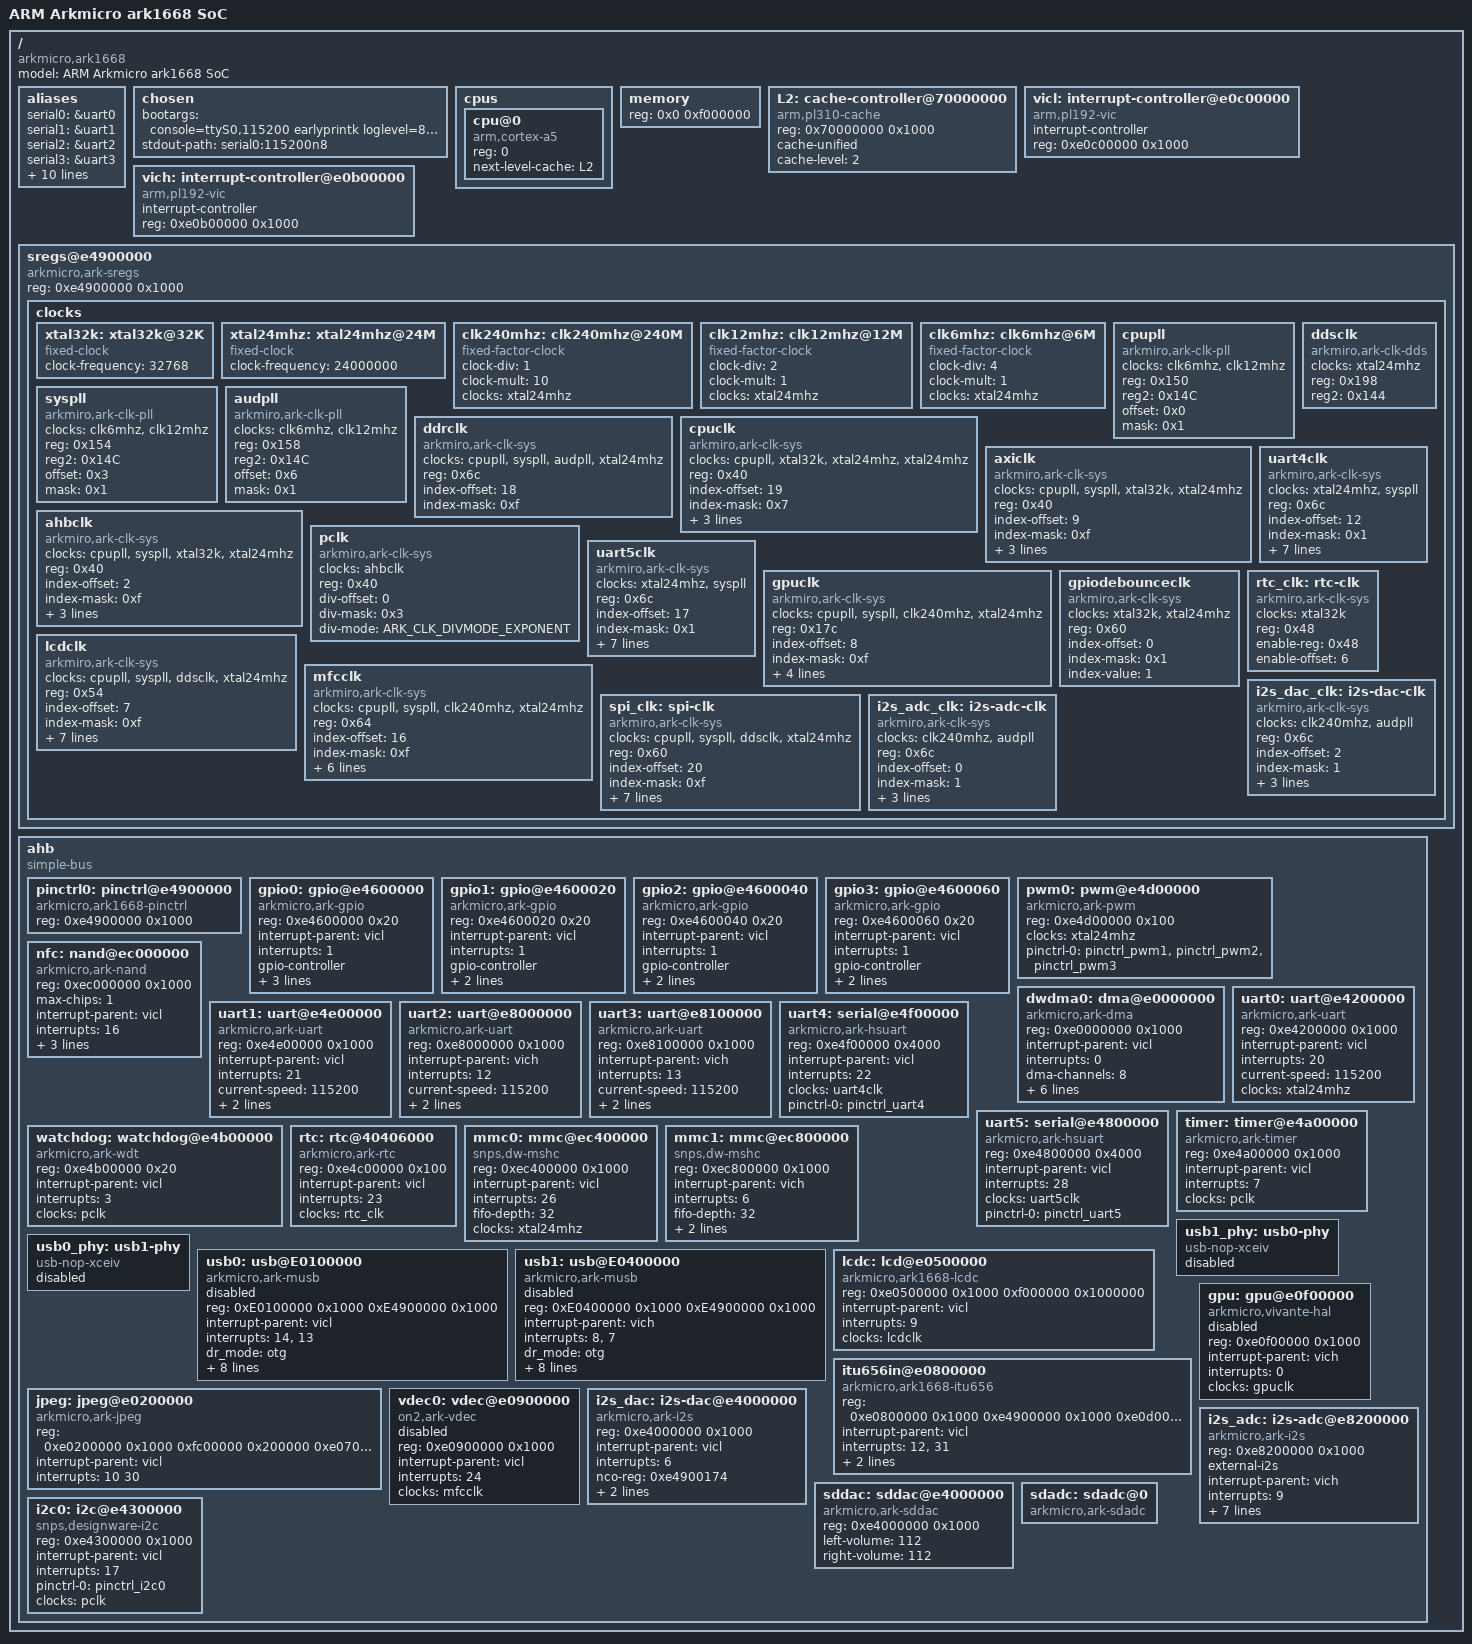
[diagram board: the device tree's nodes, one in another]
/include/ "skeleton.dtsi"
#include <dt-bindings/interrupt-controller/irq.h>
#include <dt-bindings/clock/ark-clk.h>

/ {
	model = "ARM Arkmicro ark1668 SoC";
	compatible = "arkmicro,ark1668";

	aliases {
		serial0 = &uart0;
		serial1 = &uart1;
		serial2 = &uart2;
		serial3 = &uart3;
		hsserial0 = &uart4;
		hsserial1 = &uart5;
		gpio0 = &gpio0;
		gpio1 = &gpio1;
		gpio2 = &gpio2;
		gpio3 = &gpio3;
        usb0 = &usb0;
        usb1 = &usb1;
        phy0 = &usb0_phy;
        phy1 = &usb1_phy;
	};

	chosen {
		bootargs = "console=ttyS0,115200 earlyprintk loglevel=8 clk_ignore_unused";
		stdout-path = "serial0:115200n8";
	};

	cpus {
		#address-cells = <1>;
		#size-cells = <0>;

		cpu@0 {
			device_type = "cpu";
			compatible = "arm,cortex-a5";
			reg = <0>;
			next-level-cache = <&L2>;
		};
	};

	memory {
		reg = <0x0 0xf000000>;	//2Gb
		//reg = <0x0 0x8000000>;	//1Gb
	};

	L2: cache-controller@70000000 {
		compatible = "arm,pl310-cache";
		reg = <0x70000000 0x1000>;
		cache-unified;
		cache-level = <2>;
	};

	vicl: interrupt-controller@e0c00000 {
		compatible = "arm,pl192-vic";
		interrupt-controller;
		reg = <0xe0c00000 0x1000>;
		#interrupt-cells = <1>;
	};

	vich: interrupt-controller@e0b00000 {
		compatible = "arm,pl192-vic";
		interrupt-controller;
		reg = <0xe0b00000 0x1000>;
		#interrupt-cells = <1>;
	};

	sregs@e4900000 {
		compatible = "arkmicro,ark-sregs";
		reg = <0xe4900000 0x1000>;

		clocks {
			#address-cells = <1>;
			#size-cells = <0>;

			xtal32k: xtal32k@32K {
				#clock-cells = <0>;
				compatible = "fixed-clock";
				clock-frequency = <32768>;
			};

			xtal24mhz: xtal24mhz@24M {
				#clock-cells = <0>;
				compatible = "fixed-clock";
				clock-frequency = <24000000>;
			};

			clk240mhz: clk240mhz@240M {
				#clock-cells = <0>;
				compatible = "fixed-factor-clock";
				clock-div = <1>;
				clock-mult = <10>;
				clocks = <&xtal24mhz>;
			};

			clk12mhz: clk12mhz@12M {
				#clock-cells = <0>;
				compatible = "fixed-factor-clock";
				clock-div = <2>;
				clock-mult = <1>;
				clocks = <&xtal24mhz>;
			};

			clk6mhz: clk6mhz@6M {
				#clock-cells = <0>;
				compatible = "fixed-factor-clock";
				clock-div = <4>;
				clock-mult = <1>;
				clocks = <&xtal24mhz>;
			};

			cpupll: cpupll {
				#clock-cells = <0>;
				compatible = "arkmiro,ark-clk-pll";
				clocks = <&clk6mhz>, <&clk12mhz>;
				reg = <0x150>;
				reg2 = <0x14C>;
				offset = <0x0>;
				mask = <0x1>;
			};

			syspll: syspll {
				#clock-cells = <0>;
				compatible = "arkmiro,ark-clk-pll";
				clocks = <&clk6mhz>, <&clk12mhz>;
				reg = <0x154>;
				reg2 = <0x14C>;
				offset = <0x3>;
				mask = <0x1>;
			};

			audpll: audpll {
				#clock-cells = <0>;
				compatible = "arkmiro,ark-clk-pll";
				clocks = <&clk6mhz>, <&clk12mhz>;
				reg = <0x158>;
				reg2 = <0x14C>;
				offset = <0x6>;
				mask = <0x1>;
			};

			ddsclk: ddsclk {
				#clock-cells = <0>;
				compatible = "arkmiro,ark-clk-dds";
				clocks = <&xtal24mhz>;
				reg = <0x198>;
				reg2 = <0x144>;
			};

			ddrclk: ddrclk {
				#clock-cells = <0>;
				compatible = "arkmiro,ark-clk-sys";
				clocks = <&cpupll>, <&syspll>, <&audpll>, <&xtal24mhz>;
				reg = <0x6c>;
				index-offset = <18>;
				index-mask = <0xf>;
			};

			cpuclk: cpuclk {
				#clock-cells = <0>;
				compatible = "arkmiro,ark-clk-sys";
				clocks = <&cpupll>, <&xtal32k>, <&xtal24mhz>, <&xtal24mhz>;
				reg = <0x40>;
				index-offset = <19>;
				index-mask = <0x7>;
				div-offset = <22>;
				div-mask = <0x7>;
				div-mode = <ARK_CLK_DIVMODE_NOZERO>;
			};

			axiclk: axiclk {
				#clock-cells = <0>;
				compatible = "arkmiro,ark-clk-sys";
				clocks = <&cpupll>, <&syspll>, <&xtal32k>, <&xtal24mhz>;
				reg = <0x40>;
				index-offset = <9>;
				index-mask = <0xf>;
				div-offset = <13>;
				div-mask = <0x7>;
				div-mode = <ARK_CLK_DIVMODE_NOZERO>;
			};

			ahbclk: ahbclk {
				#clock-cells = <0>;
				compatible = "arkmiro,ark-clk-sys";
				clocks = <&cpupll>, <&syspll>, <&xtal32k>, <&xtal24mhz>;
				reg = <0x40>;
				index-offset = <2>;
				index-mask = <0xf>;
				div-offset = <6>;
				div-mask = <0x7>;
				div-mode = <ARK_CLK_DIVMODE_NOZERO>;
			};

			pclk: pclk {
				#clock-cells = <0>;
				compatible = "arkmiro,ark-clk-sys";
				clocks = <&ahbclk>;
				reg = <0x40>;
				div-offset = <0>;
				div-mask = <0x3>;
				div-mode = <ARK_CLK_DIVMODE_EXPONENT>;
			};

			uart4clk: uart4clk {
				#clock-cells = <0>;
				compatible = "arkmiro,ark-clk-sys";
				clocks = <&xtal24mhz>, <&syspll>;
				reg = <0x6c>;
				index-offset = <12>;
				index-mask = <0x1>;
				index-value = <0>;
				div-offset = <8>;
				div-mask = <0xf>;
				div-value = <0>;
				div-mode = <ARK_CLK_DIVMODE_NOZERO>;
				enable-reg = <0x48 0x50>;
				enable-offset = <9 9>;
			};

			uart5clk: uart5clk {
				#clock-cells = <0>;
				compatible = "arkmiro,ark-clk-sys";
				clocks = <&xtal24mhz>, <&syspll>;
				reg = <0x6c>;
				index-offset = <17>;
				index-mask = <0x1>;
				index-value = <0>;
				div-offset = <13>;
				div-mask = <0xf>;
				div-value = <0>;
				div-mode = <ARK_CLK_DIVMODE_NOZERO>;
				enable-reg = <0x48 0x50>;
				enable-offset = <10 10>;
			};

			gpuclk: gpuclk {
				#clock-cells = <0>;
				compatible = "arkmiro,ark-clk-sys";
				clocks = <&cpupll>, <&syspll>, <&clk240mhz>, <&xtal24mhz>;
				reg = <0x17c>;
				index-offset = <8>;
				index-mask = <0xf>;
				index-value = <1>;
				div-offset = <12>;
				div-mask = <0x7>;
				div-mode = <ARK_CLK_DIVMODE_NOZERO>;
			};

			gpiodebounceclk: gpiodebounceclk {
				#clock-cells = <0>;
				compatible = "arkmiro,ark-clk-sys";
				clocks = <&xtal32k>, <&xtal24mhz>;
				reg = <0x60>;
				index-offset = <0>;
				index-mask = <0x1>;
				index-value = <1>;
			};

			lcdclk: lcdclk {
				#clock-cells = <0>;
				compatible = "arkmiro,ark-clk-sys";
				clocks = <&cpupll>, <&syspll>, <&ddsclk>, <&xtal24mhz>;
				reg = <0x54>;
				index-offset = <7>;
				index-mask = <0xf>;
				index-value = <1>;
				div-offset = <19>;
				div-mask = <0xf>;
				div-value = <1>;
				clk-can-change;
				enable-reg = <0x44 0x4c 0x50>;
				enable-offset = <8 1 4>;
			};

			mfcclk: mfcclk {
				#clock-cells = <0>;
				compatible = "arkmiro,ark-clk-sys";
				clocks = <&cpupll>, <&syspll>, <&clk240mhz>, <&xtal24mhz>;
				reg = <0x64>;
				index-offset = <16>;
				index-mask = <0xf>;
				index-value = <1>;
				div-offset = <20>;
				div-mask = <0x7>;
				div-value = <2>;
				enable-reg = <0x44 0x4c 0x50>;
				enable-offset = <9 3 22>;
			};

			rtc_clk: rtc-clk {
				#clock-cells = <0>;
				compatible = "arkmiro,ark-clk-sys";
				clocks = <&xtal32k>;
				reg = <0x48>;
				enable-reg = <0x48>;
				enable-offset = <6>;
			};

			spi_clk: spi-clk {
				#clock-cells = <0>;
				compatible = "arkmiro,ark-clk-sys";
				clocks = <&cpupll>, <&syspll>, <&ddsclk>, <&xtal24mhz>;
				reg = <0x60>;
				index-offset = <20>;
				index-mask = <0xf>;
				index-value = <1>;
				div-offset = <16>;
				div-mask = <0xf>;
				div-value = <2>;
				div-mode = <ARK_CLK_DIVMODE_PONEDOUBLE>;
				enable-reg = <0x48 0x50>;
				enable-offset = <4 13>;
			};

			i2s_dac_clk: i2s-dac-clk {
				#clock-cells = <0>;
				compatible = "arkmiro,ark-clk-sys";
				clocks = <&clk240mhz>, <&audpll>;
				reg = <0x6c>;
				index-offset = <2>;
				index-mask = <1>;
				index-value = <0>;
				enable-reg = <0x48 0x50 0x50>;
				enable-offset = <1 14 15>;
			};

			i2s_adc_clk: i2s-adc-clk {
				#clock-cells = <0>;
				compatible = "arkmiro,ark-clk-sys";
				clocks = <&clk240mhz>, <&audpll>;
				reg = <0x6c>;
				index-offset = <0>;
				index-mask = <1>;
				index-value = <0>;
				enable-reg = <0x48 0x4c 0x4c>;
				enable-offset = <17 21 22>;
			};
		};
	};

	ahb {
		compatible = "simple-bus";
		#address-cells = <1>;
		#size-cells = <1>;
		ranges;

		pinctrl0: pinctrl@e4900000 {
			compatible = "arkmicro,ark1668-pinctrl";
			reg = <0xe4900000 0x1000>;
		};

		gpio0: gpio@e4600000 {
			compatible = "arkmicro,ark-gpio";
			reg = <0xe4600000 0x20>;
			interrupt-parent = <&vicl>;
			interrupts = <1>;
			#gpio-cells = <2>;
			gpio-controller;
			interrupt-controller;
			#interrupt-cells = <2>;
			clocks = <&gpiodebounceclk>;
			gpio-ranges = <&pinctrl0 6 6 2>, <&pinctrl0 10 10 22>;
		};

		gpio1: gpio@e4600020 {
			compatible = "arkmicro,ark-gpio";
			reg = <0xe4600020 0x20>;
			interrupt-parent = <&vicl>;
			interrupts = <1>;
			#gpio-cells = <2>;
			gpio-controller;
			interrupt-controller;
			#interrupt-cells = <2>;
			gpio-ranges = <&pinctrl0 0 32 32>;
		};

		gpio2: gpio@e4600040 {
			compatible = "arkmicro,ark-gpio";
			reg = <0xe4600040 0x20>;
			interrupt-parent = <&vicl>;
			interrupts = <1>;
			#gpio-cells = <2>;
			gpio-controller;
			interrupt-controller;
			#interrupt-cells = <2>;
			gpio-ranges = <&pinctrl0 0 64 32>;
		};

		gpio3: gpio@e4600060 {
			compatible = "arkmicro,ark-gpio";
			reg = <0xe4600060 0x20>;
			interrupt-parent = <&vicl>;
			interrupts = <1>;
			#gpio-cells = <2>;
			gpio-controller;
			interrupt-controller;
			#interrupt-cells = <2>;
			gpio-ranges = <&pinctrl0 0 96 32>;
		};

		pwm0: pwm@e4d00000 {
			compatible = "arkmicro,ark-pwm";
			reg = <0xe4d00000 0x100>;
			#pwm-cells = <2>;
			clocks = <&xtal24mhz>;
			pinctrl-names = "default";
			pinctrl-0 = <&pinctrl_pwm1 &pinctrl_pwm2 &pinctrl_pwm3>;
		};

		nfc: nand@ec000000 {
			compatible = "arkmicro,ark-nand";
			reg = <0xec000000 0x1000>;
			max-chips = <1>;
			interrupt-parent = <&vicl>;
			interrupts = <16>;
			nand-bus-width = <8>;
			nand-ecc-mode = "hw_syndrome";
			nand-on-flash-bbt;
		};

		dwdma0: dma@e0000000 {
			compatible = "arkmicro,ark-dma";
			reg = <0xe0000000 0x1000>;
			interrupt-parent = <&vicl>;
			interrupts = <0>;
			dma-channels = <8>;
			dma-masters = <2>;
			chan_allocation_order = <1>;
			chan_priority = <1>;
			block_size = <0xfff>;
			data-width = <4 4>;
			/* multi-block = <1 1 1 1 1 1 1 1>; */
			clocks = <&ahbclk>;
			clock-names = "hclk";
			#dma-cells = <3>;
		};

		uart0: uart@e4200000 {
			compatible = "arkmicro,ark-uart";
			reg = <0xe4200000 0x1000>;
			interrupt-parent = <&vicl>;
			interrupts = <20>;
			current-speed = <115200>;
			clocks = <&xtal24mhz>;
			//dmas = <&dwdma0 6 1 0>, <&dwdma0 7 0 1>;
			//dma-names = "rx", "tx";
			//pinctrl-names = "default";
			//pinctrl-0 = <&pinctrl_uart0>;
		};

		uart1: uart@e4e00000 {
			compatible = "arkmicro,ark-uart";
			reg = <0xe4e00000 0x1000>;
			interrupt-parent = <&vicl>;
			interrupts = <21>;
			current-speed = <115200>;
			clocks = <&xtal24mhz>;
			pinctrl-names = "default";
			pinctrl-0 = <&pinctrl_uart1>;
		};

		uart2: uart@e8000000 {
			compatible = "arkmicro,ark-uart";
			reg = <0xe8000000 0x1000>;
			interrupt-parent = <&vich>;
			interrupts = <12>;
			current-speed = <115200>;
			clocks = <&xtal24mhz>;
			pinctrl-names = "default";
			pinctrl-0 = <&pinctrl_uart2>;
		};

		uart3: uart@e8100000 {
			compatible = "arkmicro,ark-uart";
			reg = <0xe8100000 0x1000>;
			interrupt-parent = <&vich>;
			interrupts = <13>;
			current-speed = <115200>;
			clocks = <&xtal24mhz>;
			//dmas = <&dwdma0 21 1 0>, <&dwdma0 22 0 1>;
			//dma-names = "rx", "tx";
			pinctrl-names = "default";
			pinctrl-0 = <&pinctrl_uart3>;
		};

		uart4: serial@e4f00000 {
			compatible = "arkmicro,ark-hsuart";
			reg = <0xe4f00000 0x4000>;
			interrupt-parent = <&vicl>;
			interrupts = <22>;
			clocks = <&uart4clk>;
			pinctrl-names = "default";
			pinctrl-0 = <&pinctrl_uart4>;
		};

		uart5: serial@e4800000 {
			compatible = "arkmicro,ark-hsuart";
			reg = <0xe4800000 0x4000>;
			interrupt-parent = <&vicl>;
			interrupts = <28>;
			clocks = <&uart5clk>;
			pinctrl-names = "default";
			pinctrl-0 = <&pinctrl_uart5>;
		};

		timer: timer@e4a00000 {
			compatible = "arkmicro,ark-timer";
			reg = <0xe4a00000 0x1000>;
			interrupt-parent = <&vicl>;
			interrupts = <7>;
			clocks = <&pclk>;
		};

		watchdog: watchdog@e4b00000 {
			compatible = "arkmicro,ark-wdt";
			reg = <0xe4b00000 0x20>;
			interrupt-parent = <&vicl>;
			interrupts = <3>;
			clocks = <&pclk>;
		};

		rtc: rtc@40406000 {
			compatible = "arkmicro,ark-rtc";
			reg = <0xe4c00000 0x100>;
			interrupt-parent = <&vicl>;
			interrupts = <23>;
			clocks = <&rtc_clk>;
		};

		mmc0: mmc@ec400000 {
			compatible = "snps,dw-mshc";
			#address-cells = <1>;
			#size-cells = <0>;
			reg = <0xec400000 0x1000>;
			interrupt-parent = <&vicl>;
			interrupts = <26>;
			fifo-depth = <32>;
			//dmas = <&dwdma0 8 1 0>;
			//dma-names = "rx-tx";
			clocks = <&xtal24mhz>;
			clock-names = "ciu";
		};

		mmc1: mmc@ec800000 {
			compatible = "snps,dw-mshc";
			#address-cells = <1>;
			#size-cells = <0>;
			reg = <0xec800000 0x1000>;
			interrupt-parent = <&vich>;
			interrupts = <6>;
			fifo-depth = <32>;
			dmas = <&dwdma0 9 1 0>;
			dma-names = "rx-tx";
			clocks = <&xtal24mhz>;
			clock-names = "ciu";
		};

        usb1_phy: usb0-phy {
            compatible = "usb-nop-xceiv";
            #phy-cells = <0>;
            status = "disabled";
        };

        usb0_phy: usb1-phy {
            compatible = "usb-nop-xceiv";
            #phy-cells = <0>;
            status = "disabled";
        };

        usb0: usb@E0100000{
            compatible = "arkmicro,ark-musb";
            status = "disabled";
            reg = <0xE0100000 0x1000    /* usb0 base address */
                    0xE4900000 0x1000>; /* ahb sys base address */
            reg-names = "system", "control";
			interrupt-parent = <&vicl>;
            interrupts = <14>, <13>; /* <usb0 int>, <usb0_dma_int> */
            interrupt-names = "mc", "dma";
            dr_mode = "otg";
            multipoint = <1>;
            num-eps = <6>;
            ram-bits = <12>;
            //power = <500>;
            phys = <&usb0_phy>;
            gpio-id = <76>;
            gpio-pwr = <126>;
            sys-softrest-regoffset = <0x74>;
            usb-softrest-bitoffset = <5>;
            //dma = <1>;  /* 0:false; 1:true */
            //dma_channels = <2>; /* dma ch nums */
        };

        usb1: usb@E0400000{
            compatible = "arkmicro,ark-musb";
            status = "disabled";
            reg = <0xE0400000 0x1000    /*  usb1 base address */
                    0xE4900000 0x1000>; /* ahb sys base address */
            reg-names = "system", "control";
			interrupt-parent = <&vich>;
            interrupts = <8>, <7>; /* <usb1 int>, <usb1_dma_int> */
            interrupt-names = "mc", "dma";
            dr_mode = "otg";
            multipoint = <1>;
            num-eps = <6>;
            ram-bits = <12>;
            //power = <500>;
            phys = <&usb1_phy>;
            gpio-id = <1>;
            gpio-pwr = <117>;
            sys-softrest-regoffset = <0x78>;
            usb-softrest-bitoffset = <6>;
            //dma = <1>;  /* 0:false; 1:true */
            //dma_channels = <2>; /* dma ch nums */
        };

		lcdc: lcd@e0500000 {
			compatible = "arkmicro,ark1668-lcdc";
			reg = <0xe0500000 0x1000
					0xf000000 0x1000000>;
			interrupt-parent = <&vicl>;
			interrupts = <9>;
			clocks = <&lcdclk>;
			clock-names = "lcdc_clk";
		};

		itu656in@e0800000 {
			compatible = "arkmicro,ark1668-itu656";
			reg = <0xe0800000 0x1000
				   0xe4900000 0x1000
				   0xe0d00000 0x1000
				   0xe0500000 0x1000>;
			interrupt-parent = <&vicl>;
			interrupts = <12>, <31>;
			channel = <1>;
			mirror = <0>;
		};
		
		/*itu656in@e0800000 {
                        compatible = "arkmicro,ark1668-vin";
                        reg = <0xe0800000 0x1000
                                   0xe4900000 0x1000
                                   0xe0d00000 0x1000
                                   0xe0500000 0x1000>;
                        interrupt-parent = <&vicl>;
                        interrupts = <12>, <31>;
                        channel = <1>;
                        mirror = <0>;

                        port{
                        ark656: endpoint@1{
                                remote-endpoint = <&ark7116>;
                                };
                        };

                };*/


		gpu: gpu@e0f00000 {
			compatible = "arkmicro,vivante-hal";
			reg = <0xe0f00000 0x1000>;
			interrupt-parent = <&vich>;
			interrupts = <0>;
			clocks = <&gpuclk>;
			status = "disabled";
		};

		jpeg: jpeg@e0200000 {
			compatible = "arkmicro,ark-jpeg";
			reg = <0xe0200000 0x1000
				   0xfc00000 0x200000
				   0xe0700000 0x1000>;
			interrupt-parent = <&vicl>;
			interrupts = <10 30>;
		};

		vdec0: vdec@e0900000 {
			compatible = "on2,ark-vdec";
			status = "disabled";
			reg = <0xe0900000 0x1000>;
			interrupt-parent = <&vicl>;
			interrupts = <24>;
			clocks = <&mfcclk>;
			clock-names = "vdec_clk";
		};

		i2s_dac: i2s-dac@e4000000 {
			compatible = "arkmicro,ark-i2s";
			reg = <0xe4000000 0x1000>;
			interrupt-parent = <&vicl>;
			interrupts = <6>;
			nco-reg = <0xe4900174>;
			dmas = <&dwdma0 0 1 0>, <&dwdma0 1 0 1>;
			dma-names = "rx", "tx";
			clocks = <&i2s_dac_clk>;
			#sound-dai-cells = <0>;
		};

		i2s_adc: i2s-adc@e8200000 {
			compatible = "arkmicro,ark-i2s";
			reg = <0xe8200000 0x1000>;
			external-i2s;
			interrupt-parent = <&vich>;
			interrupts = <9>;
			nco-reg = <0xe4900178>;
			dmas = <&dwdma0 23 1 0>, <&dwdma0 24 0 1>;
			dma-names = "rx", "tx";
			clocks = <&i2s_adc_clk>;
			pinctrl-0 = <&pinctrl_i2sadc_sync &pinctrl_i2sadc_sadata
						 &pinctrl_i2sadc_bclk &pinctrl_i2sadc_mclk
						 &pinctrl_i2sadc_sadata_in>;
			pinctrl-names = "default";
			#sound-dai-cells = <0>;
		};

		sddac: sddac@e4000000 {
			compatible = "arkmicro,ark-sddac";
			reg = <0xe4000000 0x1000>;
			left-volume = <112>;
			right-volume = <112>;
			#sound-dai-cells = <0>;
		};

		sdadc: sdadc@0 {
			compatible = "arkmicro,ark-sdadc";
			#sound-dai-cells = <0>;
		};

		i2c0: i2c@e4300000 {
			#address-cells = <1>;
			#size-cells = <0>;
			compatible = "snps,designware-i2c";
			reg = <0xe4300000 0x1000>;
			interrupt-parent = <&vicl>;
			interrupts = <17>;
			pinctrl-names = "default";
			pinctrl-0 = <&pinctrl_i2c0>;
			clocks = <&pclk>;
		};
	};
};
